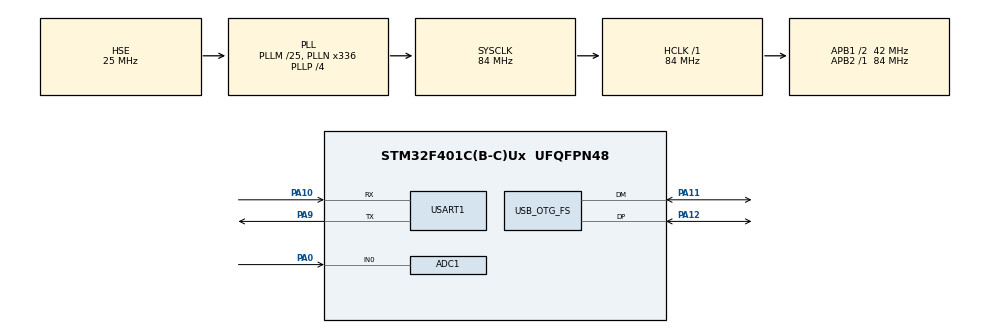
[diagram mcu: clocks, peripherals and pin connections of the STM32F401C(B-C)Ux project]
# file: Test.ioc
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ADC1.Channel-0\#ChannelRegularConversion=ADC_CHANNEL_0
ADC1.ClockPrescaler=ADC_CLOCK_SYNC_PCLK_DIV6
ADC1.DiscontinuousConvMode=ENABLE
ADC1.NbrOfConversionFlag=1
ADC1.Rank-0\#ChannelRegularConversion=1
ADC1.SamplingTime-0\#ChannelRegularConversion=ADC_SAMPLETIME_3CYCLES
ADC1.ScanConvMode=ENABLE
ADC1.master=1
Mcu.Family=STM32F4
Mcu.Name=STM32F401C(B-C)Ux
Mcu.Package=UFQFPN48
NVIC.OTG_FS_IRQn=true\:0\:0\:false\:false\:true\:false\:true\:true
NVIC.PriorityGroup=NVIC_PRIORITYGROUP_4
PA0-WKUP.Signal=SharedAnalog_PA0
PA10.Mode=Asynchronous
PA10.Signal=USART1_RX
PA11.Mode=Device_Only
PA11.Signal=USB_OTG_FS_DM
PA12.Mode=Device_Only
PA12.Signal=USB_OTG_FS_DP
PA13.Mode=Serial_Wire
PA13.Signal=SYS_JTMS-SWDIO
PA14.Mode=Serial_Wire
PA14.Signal=SYS_JTCK-SWCLK
PA9.Mode=Asynchronous
PA9.Signal=USART1_TX
PH0\ -\ OSC_IN.Mode=HSE-External-Oscillator
PH0\ -\ OSC_IN.Signal=RCC_OSC_IN
PH1\ -\ OSC_OUT.Mode=HSE-External-Oscillator
PH1\ -\ OSC_OUT.Signal=RCC_OSC_OUT
ProjectManager.HeapSize=0x200
ProjectManager.StackSize=0x400
ProjectManager.TargetToolchain=STM32CubeIDE
RCC.48MHZClocksFreq_Value=48000000
RCC.AHBFreq_Value=84000000
RCC.APB1CLKDivider=RCC_HCLK_DIV2
RCC.APB1Freq_Value=42000000
RCC.APB1TimFreq_Value=84000000
RCC.APB2Freq_Value=84000000
RCC.APB2TimFreq_Value=84000000
RCC.CortexFreq_Value=84000000
RCC.EnbaleCSS=true
RCC.HCLKFreq_Value=84000000
RCC.HSE_VALUE=25000000
RCC.HSI_VALUE=16000000
RCC.LSE_VALUE=32768
RCC.PLLM=25
RCC.PLLN=336
RCC.PLLP=RCC_PLLP_DIV4
RCC.PLLQ=7
RCC.SYSCLKFreq_VALUE=84000000
RCC.SYSCLKSource=RCC_SYSCLKSOURCE_PLLCLK
RCC.VCOOutputFreq_Value=336000000
SH.SharedAnalog_PA0.0=GPIO_Analog
SH.SharedAnalog_PA0.1=ADC1_IN0,IN0
USART1.VirtualMode=VM_ASYNC
USB_DEVICE.CLASS_NAME_FS=CDC
USB_DEVICE.VirtualMode=Cdc
USB_DEVICE.VirtualModeFS=Cdc_FS
USB_OTG_FS.VirtualMode=Device_Only
VP_USB_DEVICE_VS_USB_DEVICE_CDC_FS.Mode=CDC_FS
board=custom

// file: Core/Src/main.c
/* USER CODE BEGIN Header */
/**
  ******************************************************************************
  * @file           : main.c
  * @brief          : Main program body
  ******************************************************************************
  * @attention
  *
  * Copyright (c) 2023 STMicroelectronics.
  * All rights reserved.
  *
  * This software is licensed under terms that can be found in the LICENSE file
  * in the root directory of this software component.
  * If no LICENSE file comes with this software, it is provided AS-IS.
  *
  ******************************************************************************
  */
/* USER CODE END Header */
#include "main.h"
#include "usb_device.h"

/* USER CODE BEGIN Includes */
#include "usbd_cdc_if.h"
#include"string.h"
/* USER CODE END Includes */

ADC_HandleTypeDef hadc1;

UART_HandleTypeDef huart1;

/* USER CODE BEGIN PV */
uint16_t adc_ph=0;
float voltage=0;
float ph=0;
char *data= "dont srat v git\n\r";
/* USER CODE END PV */

void SystemClock_Config(void);
static void MX_GPIO_Init(void);
static void MX_ADC1_Init(void);
static void MX_USART1_UART_Init(void);

int main(void)
{

  /* MCU Configuration--------------------------------------------------------*/

  /* Reset of all peripherals, Initializes the Flash interface and the Systick. */
  HAL_Init();

  /* Configure the system clock */
  SystemClock_Config();

  /* Initialize all configured peripherals */
  MX_GPIO_Init();
  MX_ADC1_Init();
  MX_USB_DEVICE_Init();
  MX_USART1_UART_Init();
  /* USER CODE BEGIN 2 */
  HAL_ADC_Start(&hadc1);
  HAL_ADC_PollForConversion(&hadc1, 100);
  while(1){

	  voltage=HAL_ADC_GetValue(&hadc1);
	  	  HAL_Delay(100);
  }
  /* USER CODE END 2 */

  /* Infinite loop */
  while (1)
  {

  }
}

void SystemClock_Config(void)
{
  RCC_OscInitTypeDef RCC_OscInitStruct = {0};
  RCC_ClkInitTypeDef RCC_ClkInitStruct = {0};

  /** Configure the main internal regulator output voltage
  */
  __HAL_RCC_PWR_CLK_ENABLE();
  __HAL_PWR_VOLTAGESCALING_CONFIG(PWR_REGULATOR_VOLTAGE_SCALE2);

  /** Initializes the RCC Oscillators according to the specified parameters
  * in the RCC_OscInitTypeDef structure.
  */
  RCC_OscInitStruct.OscillatorType = RCC_OSCILLATORTYPE_HSE;
  RCC_OscInitStruct.HSEState = RCC_HSE_ON;
  RCC_OscInitStruct.PLL.PLLState = RCC_PLL_ON;
  RCC_OscInitStruct.PLL.PLLSource = RCC_PLLSOURCE_HSE;
  RCC_OscInitStruct.PLL.PLLM = 25;
  RCC_OscInitStruct.PLL.PLLN = 336;
  RCC_OscInitStruct.PLL.PLLP = RCC_PLLP_DIV4;
  RCC_OscInitStruct.PLL.PLLQ = 7;
  if (HAL_RCC_OscConfig(&RCC_OscInitStruct) != HAL_OK)
  {
    Error_Handler();
  }

  /** Initializes the CPU, AHB and APB buses clocks
  */
  RCC_ClkInitStruct.ClockType = RCC_CLOCKTYPE_HCLK|RCC_CLOCKTYPE_SYSCLK
                              |RCC_CLOCKTYPE_PCLK1|RCC_CLOCKTYPE_PCLK2;
  RCC_ClkInitStruct.SYSCLKSource = RCC_SYSCLKSOURCE_PLLCLK;
  RCC_ClkInitStruct.AHBCLKDivider = RCC_SYSCLK_DIV1;
  RCC_ClkInitStruct.APB1CLKDivider = RCC_HCLK_DIV2;
  RCC_ClkInitStruct.APB2CLKDivider = RCC_HCLK_DIV1;

  if (HAL_RCC_ClockConfig(&RCC_ClkInitStruct, FLASH_LATENCY_2) != HAL_OK)
  {
    Error_Handler();
  }

  /** Enables the Clock Security System
  */
  HAL_RCC_EnableCSS();
}

static void MX_ADC1_Init(void)
{

  ADC_ChannelConfTypeDef sConfig = {0};

  /** Configure the global features of the ADC (Clock, Resolution, Data Alignment and number of conversion)
  */
  hadc1.Instance = ADC1;
  hadc1.Init.ClockPrescaler = ADC_CLOCK_SYNC_PCLK_DIV6;
  hadc1.Init.Resolution = ADC_RESOLUTION_12B;
  hadc1.Init.ScanConvMode = ENABLE;
  hadc1.Init.ContinuousConvMode = DISABLE;
  hadc1.Init.DiscontinuousConvMode = ENABLE;
  hadc1.Init.NbrOfDiscConversion = 1;
  hadc1.Init.ExternalTrigConvEdge = ADC_EXTERNALTRIGCONVEDGE_NONE;
  hadc1.Init.ExternalTrigConv = ADC_SOFTWARE_START;
  hadc1.Init.DataAlign = ADC_DATAALIGN_RIGHT;
  hadc1.Init.NbrOfConversion = 1;
  hadc1.Init.DMAContinuousRequests = DISABLE;
  hadc1.Init.EOCSelection = ADC_EOC_SINGLE_CONV;
  if (HAL_ADC_Init(&hadc1) != HAL_OK)
  {
    Error_Handler();
  }

  /** Configure for the selected ADC regular channel its corresponding rank in the sequencer and its sample time.
  */
  sConfig.Channel = ADC_CHANNEL_0;
  sConfig.Rank = 1;
  sConfig.SamplingTime = ADC_SAMPLETIME_3CYCLES;
  if (HAL_ADC_ConfigChannel(&hadc1, &sConfig) != HAL_OK)
  {
    Error_Handler();
  }

}

static void MX_USART1_UART_Init(void)
{

  huart1.Instance = USART1;
  huart1.Init.BaudRate = 115200;
  huart1.Init.WordLength = UART_WORDLENGTH_8B;
  huart1.Init.StopBits = UART_STOPBITS_1;
  huart1.Init.Parity = UART_PARITY_NONE;
  huart1.Init.Mode = UART_MODE_TX_RX;
  huart1.Init.HwFlowCtl = UART_HWCONTROL_NONE;
  huart1.Init.OverSampling = UART_OVERSAMPLING_16;
  if (HAL_UART_Init(&huart1) != HAL_OK)
  {
    Error_Handler();
  }

}

static void MX_GPIO_Init(void)
{

  /* GPIO Ports Clock Enable */
  __HAL_RCC_GPIOH_CLK_ENABLE();
  __HAL_RCC_GPIOA_CLK_ENABLE();

}

void Error_Handler(void)
{
  __disable_irq();
  while (1)
  {
  }
}
